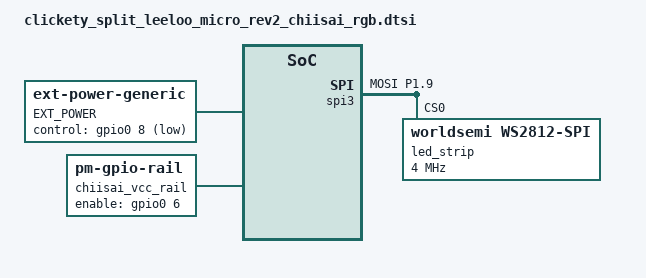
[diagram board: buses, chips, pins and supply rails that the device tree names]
/*
 * Copyright (c) 2026 Clickety Split Ltd.
 * SPDX-License-Identifier: MIT
 *
 * Leeloo-Micro v1.1/rev2 Clickety Split Chiisai RGB integration.
 *
 * This controller-specific definition is owned by the Leeloo-Micro shield.
 * Chiisai remains a generic Pro Micro-compatible controller.
 *
 * Hardware arrangement:
 *
 *   Chiisai P0.06 active-high:
 *       Enables the onboard TPS79333-EP LDO through a 100-ohm series
 *       resistor. A 10-kilohm resistor pulls the LDO enable low when the
 *       GPIO is not driven.
 *
 *       The LDO output supplies Chiisai VCC through BAT54 protection. VCC
 *       powers the Sharp display and the source side of the keyboard RGB
 *       MOSFET. The PM-aware GPIO rail keeps P0.06 asserted during normal
 *       operation and ordinary idle, then releases it before deep sleep
 *       and restores it on wake.
 *
 *   Chiisai rear pad P0.08 active-low:
 *       Connect to the Leeloo-Micro RGB MOSFET gate using a bodge wire.
 *       ZMK EXT_POWER controls this GPIO so RGB_ON, RGB_OFF, and RGB_TOG
 *       switch only the RGB LED rail.
 *
 *   Pro Micro TX0 / Arduino D1 / Chiisai P1.09:
 *       WS2812 SPI data output.
 *
 * P0.08 is the documented default bodge-wire GPIO. P0.04 is intentionally
 * preserved for possible future analog use, and P0.12 remains available as
 * an alternate spare GPIO.
 */

#include <dt-bindings/gpio/gpio.h>
#include <dt-bindings/led/led.h>
#include <zephyr/dt-bindings/pinctrl/nrf-pinctrl.h>

/ {
    chosen {
        zmk,underglow = &led_strip;
    };

    /*
     * Override Chiisai's board-level EXT_POWER assignment.
     *
     * Generic Chiisai:
     *     P0.06 active-high -> onboard TPS79333-EP LDO enable
     *
     * Leeloo-Micro rev2 Chiisai integration:
     *     P0.08 active-low -> keyboard RGB MOSFET gate
     *
     * The historical EXT_POWER node name is retained so its ZMK settings
     * identity remains stable.
     */
    EXT_POWER {
        compatible = "zmk,ext-power-generic";
        control-gpios = <&gpio0 8 GPIO_ACTIVE_LOW>;

        /*
         * Preserve Chiisai's established conservative enable delay.
         * Physical testing confirmed normal startup and RGB operation.
         * The 30-minute production sleep/wake test also passed.
         * Electrical rail waveforms were not oscilloscope-verified.
         */
        init-delay-ms = <50>;
    };
};

/*
 * The PM-aware GPIO rail keeps the Chiisai TPS79333-EP LDO enabled during
 * normal operation and ordinary idle.
 *
 * After ZMK EXT_POWER is redirected to P0.08, P0.06 independently supplies
 * VCC for the display and the source side of the RGB MOSFET. Device PM
 * releases P0.06 before deep sleep and restores it on wake. The resistor
 * to ground provides the intended discharge path for the Chiisai
 * stabilization capacitor after the display/VCC rail turns off.
 *
 * Physical testing found clean display shutdown with no retained image or
 * visible artifact. The discharge behaviour is electrically consistent
 * with the design but was not oscilloscope-verified.
 */
/ {
    /*
     * Keep Chiisai VCC available during active use and ordinary ZMK idle.
     * Device PM disables P0.06 immediately before deep sleep, allowing the
     * TPS79333-EP output and attached Sharp Memory LCD supply to shut down.
     */
    chiisai_vcc_rail: chiisai-vcc-rail {
        compatible = "zmk,pm-gpio-rail";
        enable-gpios = <&gpio0 6 GPIO_ACTIVE_HIGH>;
        init-delay-ms = <50>;
        status = "okay";
    };
};

&pinctrl {
    leeloo_micro_rev2_chiisai_spi3_default:
        leeloo_micro_rev2_chiisai_spi3_default {
        group1 {
            /*
             * Pro Micro TX0 / Arduino D1 maps to Chiisai P1.09.
             */
            psels = <NRF_PSEL(SPIM_MOSI, 1, 9)>;
        };
    };

    leeloo_micro_rev2_chiisai_spi3_sleep:
        leeloo_micro_rev2_chiisai_spi3_sleep {
        group1 {
            psels = <NRF_PSEL(SPIM_MOSI, 1, 9)>;
            low-power-enable;
        };
    };
};

&spi3 {
    compatible = "nordic,nrf-spim";
    status = "okay";

    pinctrl-0 = <&leeloo_micro_rev2_chiisai_spi3_default>;
    pinctrl-1 = <&leeloo_micro_rev2_chiisai_spi3_sleep>;
    pinctrl-names = "default", "sleep";

    led_strip: ws2812@0 {
        compatible = "worldsemi,ws2812-spi";
        status = "okay";

        reg = <0>;
        spi-max-frequency = <4000000>;

        /* Leeloo-Micro v1.1/rev2 contains 20 GRB LEDs per half. */
        chain-length = <20>;
        spi-one-frame = <0x70>;
        spi-zero-frame = <0x40>;

        color-mapping = <
            LED_COLOR_ID_GREEN
            LED_COLOR_ID_RED
            LED_COLOR_ID_BLUE
        >;
    };
};
